AUTOSAR XML (schema 4-3-0)
package /ComponentTypes
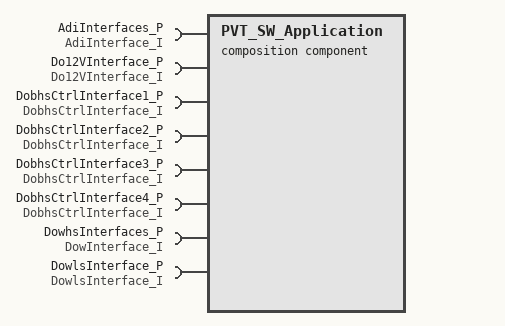
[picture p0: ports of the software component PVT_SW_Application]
  composition sw component type PVT_SW_Application
    8 x require port:
      AdiInterfaces_P: required-com-specs=[GetAdiPinState, GetAdiPinStateAll, GetPullUpState, SetPullUp], required-interface=AdiInterface_I
      Do12VInterface_P: required-com-specs=[GetDo12VPinsState, SetDcdc12VActive, SetDo12VLivingActive, SetDo12VParkedActive], required-interface=Do12VInterface_I
      DobhsCtrlInterface1_P: required-com-specs=[GetDobhsPinState, SetDobhsActive], required-interface=DobhsCtrlInterface_I
      DobhsCtrlInterface2_P: required-com-specs=[GetDobhsPinState, SetDobhsActive], required-interface=DobhsCtrlInterface_I
      DobhsCtrlInterface3_P: required-com-specs=[SetDobhsActive, GetDobhsPinState], required-interface=DobhsCtrlInterface_I
      DobhsCtrlInterface4_P: required-com-specs=[GetDobhsPinState, SetDobhsActive], required-interface=DobhsCtrlInterface_I
      DowhsInterfaces_P: required-com-specs=[GetDoPinStateOne, SetDowActive], required-interface=DowInterface_I
      DowlsInterface_P: required-com-specs=[GetDoPinStateOne, SetDowlsActive], required-interface=DowlsInterface_I
